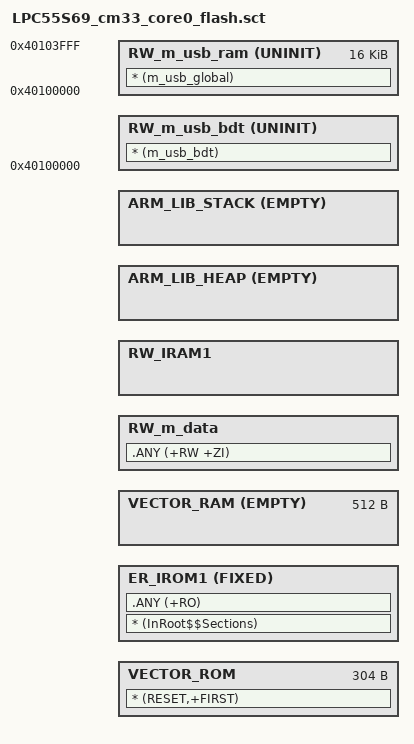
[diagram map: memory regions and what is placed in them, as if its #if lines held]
#!armclang --target=arm-arm-none-eabi -march=armv8-m.main -E -x c
/*
** ###################################################################
**     Processors:          LPC55S69JBD100_cm33_core0
**                          LPC55S69JET98_cm33_core0
**
**     Compiler:            Keil ARM C/C++ Compiler
**     Reference manual:    LPC55xx/LPC55Sxx User manual Rev.0.2  15 Aug 2018
**     Version:             rev. 1.0, 2018-08-22
**     Build:               b181008
**
**     Abstract:
**         Linker file for the Keil ARM C/C++ Compiler
**
**     Copyright 2016 Freescale Semiconductor, Inc.
**     Copyright 2016-2018 NXP
**     All rights reserved.
**
**     SPDX-License-Identifier: BSD-3-Clause
**
**     http:                 www.nxp.com
**     mail:                 support@nxp.com
**
** ###################################################################
*/
#include "../../../partition/region_defs.h"

#define __ram_vector_table__            1

#if (defined(__ram_vector_table__))
  #define __ram_vector_table_size__    0x00000200
#else
  #define __ram_vector_table_size__    0x00000000
#endif

/* USB BDT size */
#define usb_bdt_size                   0x0

/* Sizes */
#if !defined(MBED_BOOT_STACK_SIZE)
  #define MBED_BOOT_STACK_SIZE 0x400
#endif

#if (defined(__stack_size__))
  #define Stack_Size                   __stack_size__
#else
  #define Stack_Size                   MBED_BOOT_STACK_SIZE
#endif

#if (defined(__heap_size__))
  #define Heap_Size                    __heap_size__
#else
  #define Heap_Size                    0x0400
#endif

#if !defined(MBED_ROM_START)
  #define MBED_ROM_START      NS_CODE_START
#endif

#if !defined(MBED_APP_START)
  #define MBED_APP_START      MBED_ROM_START
#endif

#if !defined(MBED_ROM_SIZE)
  #define MBED_ROM_SIZE       NS_CODE_SIZE
#endif

#if !defined(MBED_APP_SIZE)
  #define MBED_APP_SIZE       MBED_ROM_SIZE
#endif

#if !defined(MBED_RAM_START)
  #define MBED_RAM_START      NS_DATA_START
#endif

#if !defined(MBED_RAM_SIZE)
  #define MBED_RAM_SIZE       NS_DATA_SIZE
#endif

#if !defined(NVIC_INTERRUPT_NUM)
  #define NVIC_INTERRUPT_NUM     60
#endif

#if !defined(EXCEPTION_VECT_NUM)
  #define EXCEPTION_VECT_NUM     16
#endif

#if !defined(MEMORY_ADDR_SIZE_IN_BYTE)
  #define MEMORY_ADDR_SIZE_IN_BYTE     4
#endif

#define  m_interrupts_start            MBED_APP_START
#define  m_interrupts_size             ((NVIC_INTERRUPT_NUM + EXCEPTION_VECT_NUM) * MEMORY_ADDR_SIZE_IN_BYTE)

#define  m_text_start                  MBED_APP_START + m_interrupts_size
#define  m_text_size                   MBED_APP_SIZE - m_interrupts_size

#define  m_interrupts_ram_start        MBED_RAM_START
#define  m_interrupts_ram_size         __ram_vector_table_size__

#define  m_data_start                  (m_interrupts_ram_start + m_interrupts_ram_size)
#define  m_data_size                   (MBED_RAM_SIZE - m_interrupts_ram_size)

#define  m_usb_sram_start              0x40100000
#define  m_usb_sram_size               0x00004000

LR_IROM1 m_interrupts_start (AlignExpr(m_text_start, 8)+m_text_size-m_interrupts_start) {   ; load region size_region

  VECTOR_ROM m_interrupts_start m_interrupts_size { ; load address = execution address
    * (RESET,+FIRST)
  }

  ER_IROM1 AlignExpr(m_text_start, 8) FIXED m_text_size { ; load address = execution address
    * (InRoot$$Sections)
    .ANY (+RO)
  }

#if (defined(__ram_vector_table__))
  VECTOR_RAM m_interrupts_ram_start EMPTY m_interrupts_ram_size {
  }
#else
  VECTOR_RAM m_interrupts_start EMPTY 0 {
  }
#endif

  RW_m_data m_data_start m_data_size { ; RW data
    .ANY (+RW +ZI)
  }
  RW_IRAM1 ImageLimit(RW_m_data)  {
  }
  ARM_LIB_HEAP AlignExpr(+0, 16) EMPTY (m_data_start + m_data_size - Stack_Size - AlignExpr(ImageLimit(RW_IRAM1), 16)) {
  }
  ARM_LIB_STACK m_data_start+m_data_size EMPTY -Stack_Size { ; Stack region growing down
  }

  RW_m_usb_bdt m_usb_sram_start UNINIT usb_bdt_size {
    * (m_usb_bdt)
  }

  RW_m_usb_ram (m_usb_sram_start + usb_bdt_size) UNINIT (m_usb_sram_size - usb_bdt_size) {
    * (m_usb_global)
  }
}

